# STM32C552 register map
File version: 0.3
CPU: CM33 r0p4, little endian, MPU, FPU, 4 interrupt priority bits
Registers are 32-bit, read-write, reset 0x0 unless marked. A register's access mark holds for its fields unless they carry their own. Offsets are from the block's base; [hi:lo] are bit positions; {n}, {i} and the like mark numbered series.

## GPIOA — GPIOA address block description
Base 0x42020000
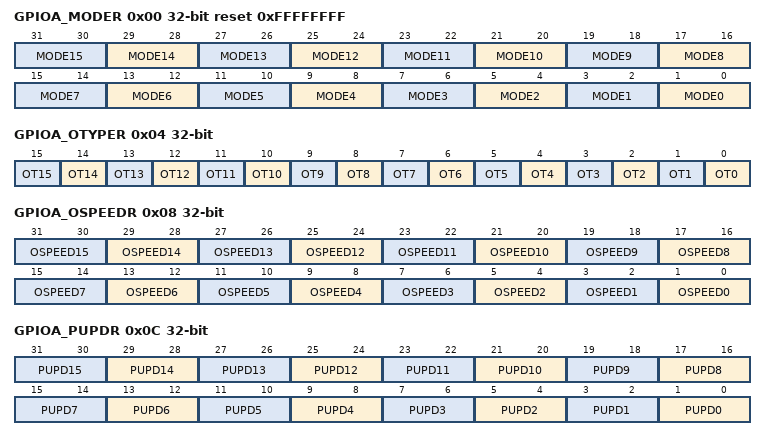
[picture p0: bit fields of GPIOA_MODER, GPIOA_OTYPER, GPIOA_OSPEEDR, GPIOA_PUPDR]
0x00 GPIOA_MODER reset 0xFFFFFFFF — GPIO port mode register
  [all] fields
    0=Input mode; 1=General purpose output mode; 2=Alternate function mode; 3=Analog mode (reset state)
  [2n+1:2n] MODE{n} (n=0..15) — Port x configuration I/O pin y
0x04 GPIOA_OTYPER — GPIO port output type register
  [all] fields
    0=Output push-pull (reset state); 1=Output open-drain
  [n] OT{n} (n=0..15) — Port x configuration I/O pin y
0x08 GPIOA_OSPEEDR — GPIO port output speed register
  [all] fields
    0=Low speed; 1=Medium speed; 2=High speed; 3=Very-high speed
  [2n+1:2n] OSPEED{n} (n=0..15) — Port x configuration I/O pin y
0x0C GPIOA_PUPDR — GPIO port pull-up/pull-down register
  [all] fields
    0=No pull-up, pull-down; 1=Pull-up; 2=Pull-down
  [2n+1:2n] PUPD{n} (n=0..15) — Port x configuration I/O pin y
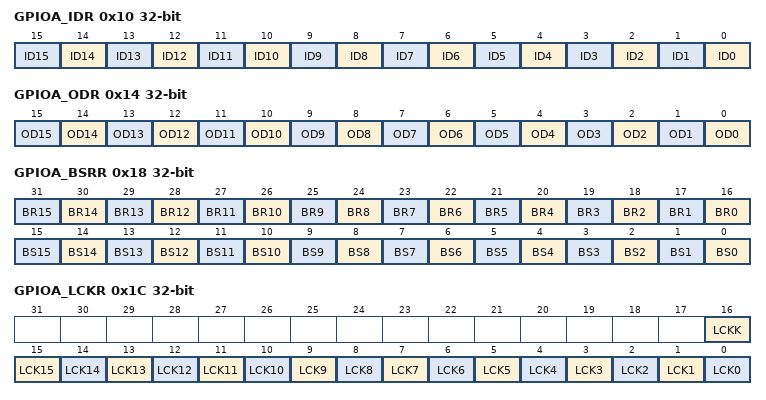
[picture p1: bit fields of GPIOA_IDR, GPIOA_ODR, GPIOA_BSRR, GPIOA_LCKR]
0x10 GPIOA_IDR ro (reset mask 0xFFFF0000) — GPIO port input data register
  [n] ID{n} (n=0..15) — Port x input data I/O pin y
0x14 GPIOA_ODR — GPIO port output data register
  [n] OD{n} (n=0..15) — Port output data I/O pin y
0x18 GPIOA_BSRR wo — GPIO port bit set/reset register
  [n+16] BR{n} (n=0..15) — Port x reset I/O pin y
    0=No action on the corresponding ODy bit; 1=Resets the corresponding ODy bit
  [n] BS{n} (n=0..15) — Port x set I/O pin y
    0=No action on the corresponding ODy bit; 1=Sets the corresponding ODy bit
0x1C GPIOA_LCKR — GPIO port configuration lock register
  [16] LCKK — Lock key
    0=Port configuration lock key not active; 1=Port configuration lock key active
  [n] LCK{n} (n=0..15) — Port x lock I/O pin y
    0=Port configuration not locked; 1=Port configuration locked
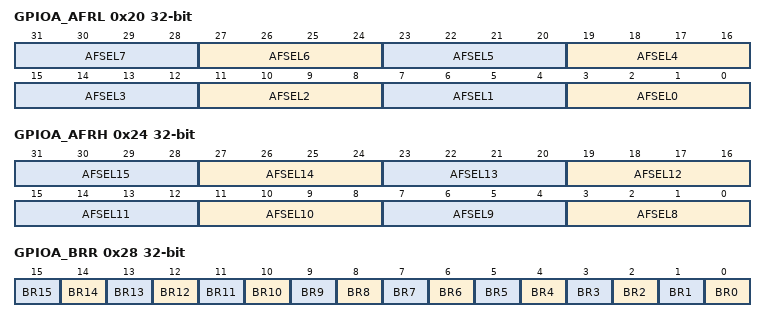
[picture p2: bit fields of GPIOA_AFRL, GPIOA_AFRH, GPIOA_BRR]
0x20 GPIOA_AFRL — GPIO alternate function low register
  [all] fields
    {v}=AF{v} (v=0..15)
  [4n+3:4n] AFSEL{n} (n=0..7) — Alternate function selection for port x I/O pin y
0x24 GPIOA_AFRH — GPIO alternate function high register
  [all] fields
    {v}=AF{v} (v=0..15)
  [4n-29:4n-32] AFSEL{n} (n=8..15) — Alternate function selection for port x I/O pin y
0x28 GPIOA_BRR wo — GPIO port bit reset register
  [all] fields
    0=No action on the corresponding ODy bit; 1=Reset the corresponding ODy bit
  [n] BR{n} (n=0..15) — Port x reset IO pin y

## GPIOB — GPIOB address block description
Base 0x42020400
Registers as GPIOA (with GPIOA read as GPIOB).

## GPIOC — GPIOC address block description
Base 0x42020800
Registers as GPIOA (with GPIOA read as GPIOC).

## GPIOD — GPIOD address block description
Base 0x42020C00
Registers as GPIOA (with GPIOA read as GPIOD).

## GPIOE — GPIOE address block description
Base 0x42021000
Registers as GPIOA (with GPIOA read as GPIOE).

## GPIOH — GPIOH address block description
Base 0x42021C00
Registers as GPIOA (with GPIOA read as GPIOH).

## ICACHE — ICACHE register block
Base 0x40030400
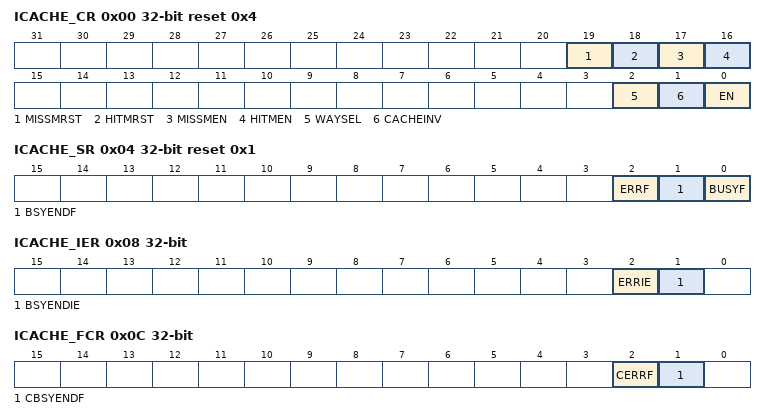
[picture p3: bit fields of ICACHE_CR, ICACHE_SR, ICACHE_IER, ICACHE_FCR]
0x00 ICACHE_CR reset 0x4 — ICACHE control register
  [19] MISSMRST — miss monitor reset
    0=release the cache miss monitor reset (needed to enable the counting); 1=reset cache miss monitor
  [18] HITMRST — hit monitor reset
    0=release the cache miss monitor reset (needed to enable the counting); 1=reset cache hit monitor
  [17] MISSMEN — miss monitor enable
    0=cache miss monitor switched off. Stopping the monitor does not reset it.; 1=cache miss monitor enabled
  [16] HITMEN — hit monitor enable
    0=cache hit monitor switched off. Stopping the monitor does not reset it.; 1=cache hit monitor enabled
  [2] WAYSEL — cache associativity mode selection
    0=direct mapped cache (1-way cache); 1=n-way set associative cache (reset value)
  [1] CACHEINV wo — cache invalidation
    0=no effect; 1=invalidate entire cache (all cache lines valid bit = 0)
  [0] EN — enable
    0=cache disabled; 1=cache enabled
0x04 ICACHE_SR ro reset 0x1 — ICACHE status register
  [2] ERRF — cache error flag
    0=no error; 1=an error occurred during the operation (cacheable write)
  [1] BSYENDF — busy end flag
    0=cache busy; 1=full invalidate CACHEINV operation finished
  [0] BUSYF — busy flag
    0=cache not busy on a CACHEINV operation; 1=cache executing a full invalidate CACHEINV operation
0x08 ICACHE_IER — ICACHE interrupt enable register
  [2] ERRIE — interrupt enable on cache error
    0=interrupt disabled on error; 1=interrupt enabled on error
  [1] BSYENDIE — interrupt enable on busy end
    0=interrupt disabled on busy end; 1=interrupt enabled on busy end
0x0C ICACHE_FCR wo — ICACHE flag clear register
  [2] CERRF — clear cache error flag
    0=no effect; 1=clears ERRF flag in ICACHE_SR
  [1] CBSYENDF — clear busy end flag
    0=no effect; 1=clears BSYENDF flag in ICACHE_SR
0x10 ICACHE_HMONR ro — ICACHE hit monitor register
  [31:0] HITMON — cache hit monitor counter
0x14 ICACHE_MMONR ro — ICACHE miss monitor register
  [15:0] MISSMON — cache miss monitor counter
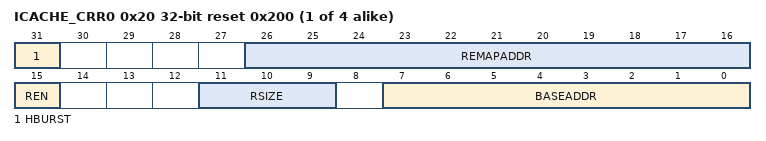
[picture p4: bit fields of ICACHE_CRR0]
{0x20+4i} ICACHE_CRR{i} reset 0x200 (i=0..3) — ICACHE region {i} configuration register
  [31] HBURST — output burst type for region x
    0=WRAP; 1=INCR
  [26:16] REMAPADDR — remapped address for region x
  [15] REN — enable for region x
    0=disabled; 1=enabled
  [11:9] RSIZE — size for region x
    1=2 Mbytes; 2=4 Mbytes; 3=8 Mbytes; 4=16 Mbytes; 5=32 Mbytes; 6=64 Mbytes; 7=128 Mbytes
  [7:0] BASEADDR — base address for region x

## Notices in the file
Copyright (c) 2022 STMicroelectronics.
SPDX-License-Identifier: Apache-2.0
Licensed under the Apache License, Version 2.0 (the "License");
you may not use this file except in compliance with the License.
You may obtain a copy of the License at
http://www.apache.org/licenses/LICENSE-2.0
Unless required by applicable law or agreed to in writing, software
distributed under the License is distributed on an "AS IS" BASIS,
WITHOUT WARRANTIES OR CONDITIONS OF ANY KIND, either express or implied.
See the License for the specific language governing permissions and
limitations under the License.
